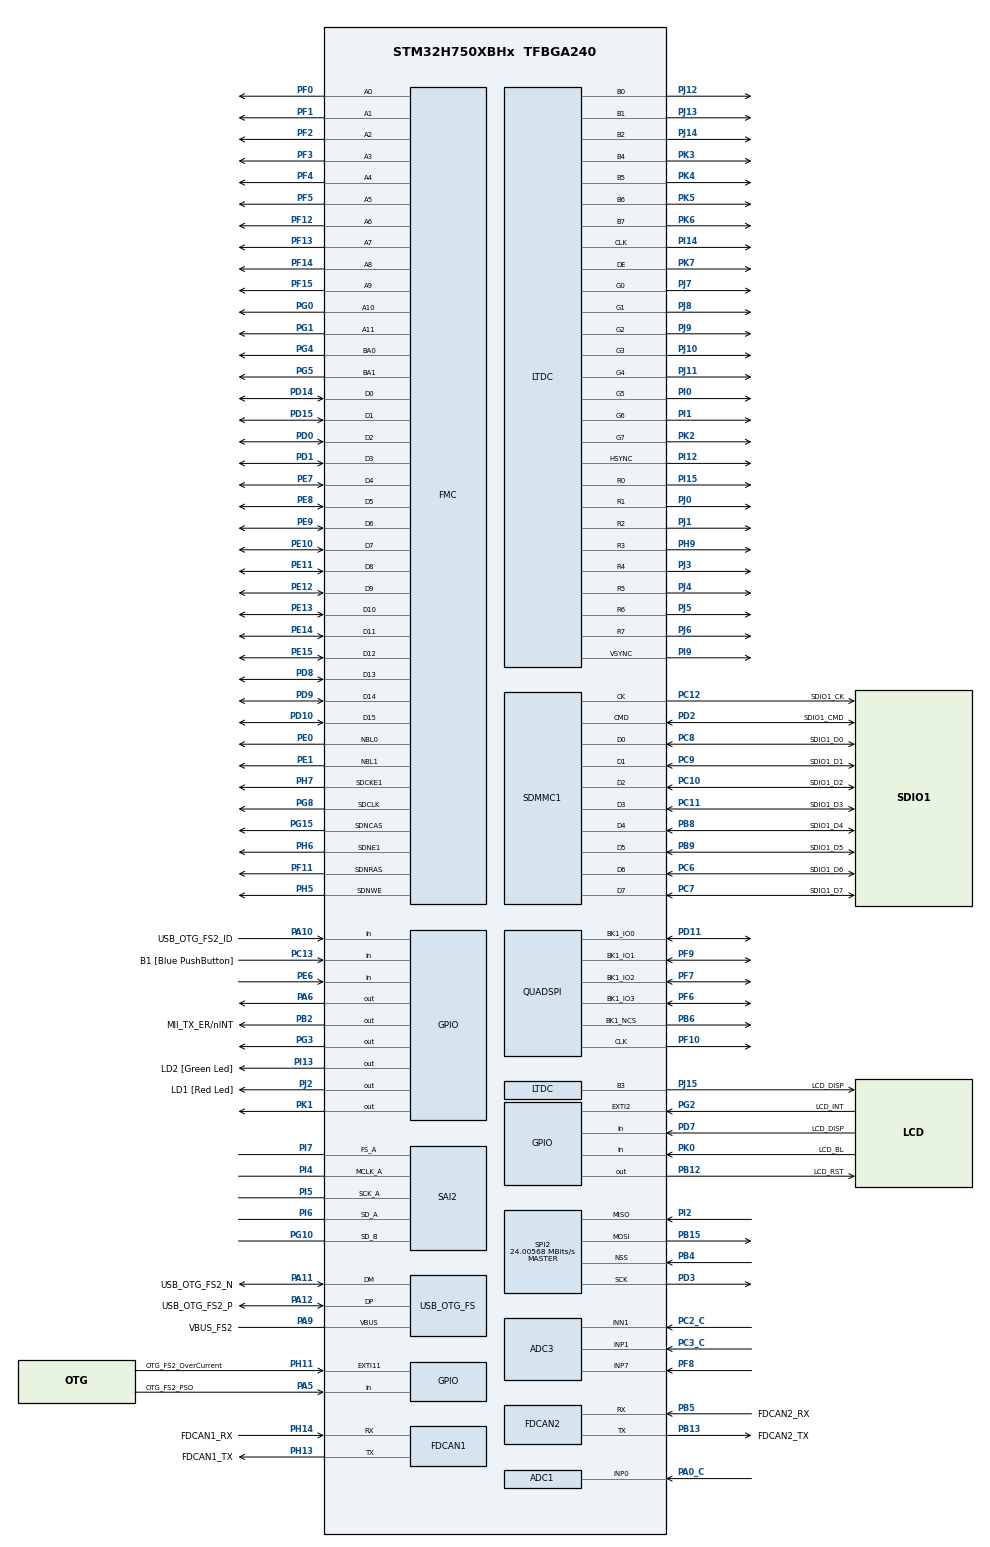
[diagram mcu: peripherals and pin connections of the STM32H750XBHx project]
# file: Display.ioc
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ADC1.Channel-0\#ChannelRegularConversion=ADC_CHANNEL_0
ADC1.NbrOfConversionFlag=1
ADC1.OffsetNumber-0\#ChannelRegularConversion=ADC_OFFSET_NONE
ADC1.Rank-0\#ChannelRegularConversion=1
ADC1.SamplingTime-0\#ChannelRegularConversion=ADC_SAMPLETIME_1CYCLE_5
ADC1.master=1
ADC2.Channel-0\#ChannelRegularConversion=ADC_CHANNEL_0
ADC2.NbrOfConversionFlag=1
ADC2.OffsetNumber-0\#ChannelRegularConversion=ADC_OFFSET_NONE
ADC2.Rank-0\#ChannelRegularConversion=1
ADC2.SamplingTime-0\#ChannelRegularConversion=ADC_SAMPLETIME_1CYCLE_5
ADC3.Channel-0\#ChannelRegularConversion=ADC_CHANNEL_7
ADC3.NbrOfConversionFlag=1
ADC3.OffsetNumber-0\#ChannelRegularConversion=ADC_OFFSET_NONE
ADC3.Rank-0\#ChannelRegularConversion=1
ADC3.SamplingTime-0\#ChannelRegularConversion=ADC_SAMPLETIME_1CYCLE_5
FDCAN1.CalculateBaudRateNominal=1000236
FDCAN1.CalculateTimeBitNominal=999
FDCAN1.CalculateTimeQuantumNominal=333.2544378698225
FDCAN2.CalculateBaudRateNominal=1000236
FDCAN2.CalculateTimeBitNominal=999
FDCAN2.CalculateTimeQuantumNominal=333.2544378698225
LTDC.ActiveH=272
LTDC.ActiveW=480
LTDC.HBP=13
LTDC.HFP=32
LTDC.HSync=41
LTDC.VSync=10
Mcu.Family=STM32H7
Mcu.Name=STM32H750XBHx
Mcu.Package=TFBGA240
NVIC.PriorityGroup=NVIC_PRIORITYGROUP_4
PA0_C.Signal=ADCx_INP0
PA1.GPIO_Label=MII_RX_CLK
PA1.Signal=ETH_RX_CLK
PA10.GPIO_Label=USB_OTG_FS2_ID
PA10.Signal=GPIO_Input
PA11.GPIO_Label=USB_OTG_FS2_N
PA11.Mode=Device_Only
PA11.Signal=USB_OTG_FS_DM
PA12.GPIO_Label=USB_OTG_FS2_P
PA12.Mode=Device_Only
PA12.Signal=USB_OTG_FS_DP
PA13\ (JTMS/SWDIO).Mode=JTAG_4_pins
PA13\ (JTMS/SWDIO).Signal=DEBUG_JTMS-SWDIO
PA14\ (JTCK/SWCLK).Mode=JTAG_4_pins
PA14\ (JTCK/SWCLK).Signal=DEBUG_JTCK-SWCLK
PA15\ (JTDI).Mode=JTAG_4_pins
PA15\ (JTDI).Signal=DEBUG_JTDI
PA1_C.Signal=ADCx_INP1
PA2.GPIO_Label=MII_MDIO
PA2.Signal=ETH_MDIO
PA5.GPIO_Label=OTG_FS2_PSO
PA5.Signal=GPIO_Input
PA6.Signal=GPIO_Output
PA7.GPIO_Label=MII_RX_DV
PA7.Signal=ETH_RX_DV
PA8.Signal=S_TIM1_CH1
PA9.GPIO_Label=VBUS_FS2
PA9.Mode=Activate_VBUS
PA9.Signal=USB_OTG_FS_VBUS
PB0.GPIO_Label=MII_RX_D2
PB0.Signal=ETH_RXD2
PB1.GPIO_Label=MII_RX_D3
PB1.Signal=ETH_RXD3
PB12.GPIO_Label=LCD_RST
PB12.Signal=GPIO_Output
PB13.GPIO_Label=FDCAN2_TX
PB13.Mode=FDCAN_Activate
PB13.Signal=FDCAN2_TX
PB15.Mode=Full_Duplex_Master
PB15.Signal=SPI2_MOSI
PB2.GPIO_Label=MII_TX_ER/nINT
PB2.Signal=GPIO_Output
PB3\ (JTDO/TRACESWO).Mode=JTAG_4_pins
PB3\ (JTDO/TRACESWO).Signal=DEBUG_JTDO-SWO
PB4\ (NJTRST).Mode=NSS_Signal_Hard_Input
PB4\ (NJTRST).Signal=SPI2_NSS
PB5.GPIO_Label=FDCAN2_RX
PB5.Mode=FDCAN_Activate
PB5.Signal=FDCAN2_RX
PB6.Mode=Single Bank 1
PB6.Signal=QUADSPI_BK1_NCS
PB8.GPIO_Label=SDIO1_D4
PB8.Mode=mmc_8_bits_Wide_bus
PB8.Signal=SDMMC1_D4
PB9.GPIO_Label=SDIO1_D5
PB9.Mode=mmc_8_bits_Wide_bus
PB9.Signal=SDMMC1_D5
PC0.Signal=ADCx_INP10
PC1.GPIO_Label=MII_MDC
PC1.Signal=ETH_MDC
PC10.GPIO_Label=SDIO1_D2
PC10.Mode=mmc_8_bits_Wide_bus
PC10.Signal=SDMMC1_D2
PC11.GPIO_Label=SDIO1_D3
PC11.Mode=mmc_8_bits_Wide_bus
PC11.Signal=SDMMC1_D3
PC12.GPIO_Label=SDIO1_CK
PC12.Mode=mmc_8_bits_Wide_bus
PC12.Signal=SDMMC1_CK
PC13.GPIO_Label=B1 [Blue PushButton]
PC13.Signal=GPIO_Input
PC14-OSC32_IN\ (OSC32_IN).GPIO_Label=OSC32_IN
PC14-OSC32_IN\ (OSC32_IN).Mode=LSE-External-Clock-Source
PC14-OSC32_IN\ (OSC32_IN).Signal=RCC_OSC32_IN
PC15-OSC32_OUT\ (OSC32_OUT).GPIO_Label=OSC32_OUT
PC15-OSC32_OUT\ (OSC32_OUT).Signal=RCC_OSC32_OUT
PC2.GPIO_Label=MII_TXD2
PC2.Signal=ETH_TXD2
PC2_C.Signal=SharedAnalog_PC2
PC3.GPIO_Label=MII_TX_CLK
PC3.Signal=ETH_TX_CLK
PC3_C.Mode=IN1-Differential
PC3_C.Signal=ADC3_INP1
PC4.GPIO_Label=MII_RXD0
PC4.Signal=ETH_RXD0
PC5.GPIO_Label=MII_RXD1
PC5.Signal=ETH_RXD1
PC6.GPIO_Label=SDIO1_D6
PC6.Mode=mmc_8_bits_Wide_bus
PC6.Signal=SDMMC1_D6
PC7.GPIO_Label=SDIO1_D7
PC7.Mode=mmc_8_bits_Wide_bus
PC7.Signal=SDMMC1_D7
PC8.GPIO_Label=SDIO1_D0
PC8.Mode=mmc_8_bits_Wide_bus
PC8.Signal=SDMMC1_D0
PC9.GPIO_Label=SDIO1_D1
PC9.Mode=mmc_8_bits_Wide_bus
PC9.Signal=SDMMC1_D1
PD0.Signal=FMC_D2_DA2
PD1.Signal=FMC_D3_DA3
PD10.Signal=FMC_D15_DA15
PD11.Mode=Single Bank 1
PD11.Signal=QUADSPI_BK1_IO0
PD14.Signal=FMC_D0_DA0
PD15.Signal=FMC_D1_DA1
PD2.GPIO_Label=SDIO1_CMD
PD2.Mode=mmc_8_bits_Wide_bus
PD2.Signal=SDMMC1_CMD
PD3.Mode=Full_Duplex_Master
PD3.Signal=SPI2_SCK
PD7.GPIO_Label=LCD_DISP
PD7.Signal=GPIO_Input
PD8.Signal=FMC_D13_DA13
PD9.Signal=FMC_D14_DA14
PE0.Signal=FMC_NBL0
PE1.Signal=FMC_NBL1
PE10.Signal=FMC_D7_DA7
PE11.Signal=FMC_D8_DA8
PE12.Signal=FMC_D9_DA9
PE13.Signal=FMC_D10_DA10
PE14.Signal=FMC_D11_DA11
PE15.Signal=FMC_D12_DA12
PE2.GPIO_Label=MII_TXD3
PE2.Signal=ETH_TXD3
PE4.Signal=SAI4_D2
PE5.Signal=SAI4_CK2
PE6.GPIO_PuPd=GPIO_PULLUP
PE6.Signal=GPIO_Input
PE7.Signal=FMC_D4_DA4
PE8.Signal=FMC_D5_DA5
PE9.Signal=FMC_D6_DA6
PF0.Signal=FMC_A0
PF1.Signal=FMC_A1
PF10.Mode=Single Bank 1
PF10.Signal=QUADSPI_CLK
PF11.Signal=FMC_SDNRAS
PF12.Signal=FMC_A6
PF13.Signal=FMC_A7
PF14.Signal=FMC_A8
PF15.Signal=FMC_A9
PF2.Signal=FMC_A2
PF3.Signal=FMC_A3
PF4.Signal=FMC_A4
PF5.Signal=FMC_A5
PF6.Mode=Single Bank 1
PF6.Signal=QUADSPI_BK1_IO3
PF7.Mode=Single Bank 1
PF7.Signal=QUADSPI_BK1_IO2
PF8.Mode=IN7-Single-Ended
PF8.Signal=ADC3_INP7
PF9.Mode=Single Bank 1
PF9.Signal=QUADSPI_BK1_IO1
PG0.Signal=FMC_A10
PG1.Signal=FMC_A11
PG10.Mode=SAI_B_SyncSlave
PG10.Signal=SAI2_SD_B
PG11.GPIO_Label=MII_TX_EN
PG11.Signal=ETH_TX_EN
PG12.GPIO_Label=MII_TXD1
PG12.Signal=ETH_TXD1
PG13.GPIO_Label=MII_TXD0
PG13.Signal=ETH_TXD0
PG15.Signal=FMC_SDNCAS
PG2.GPIO_Label=LCD_INT
PG2.Signal=GPXTI2
PG3.Signal=GPIO_Output
PG4.Signal=FMC_A14_BA0
PG5.Signal=FMC_A15_BA1
PG7.GPIO_Label=audio_Int
PG7.Signal=SAI1_MCLK_A
PG8.Signal=FMC_SDCLK
PH0-OSC_IN\ (PH0).GPIO_Label=OSC_IN
PH0-OSC_IN\ (PH0).Mode=HSE-External-Clock-Source
PH0-OSC_IN\ (PH0).Signal=RCC_OSC_IN
PH1-OSC_OUT\ (PH1).GPIO_Label=OSC_OUT
PH1-OSC_OUT\ (PH1).Signal=RCC_OSC_OUT
PH11.GPIO_Label=OTG_FS2_OverCurrent
PH11.Signal=GPXTI11
PH13.GPIO_Label=FDCAN1_TX
PH13.Mode=FDCAN_Activate
PH13.Signal=FDCAN1_TX
PH14.GPIO_Label=FDCAN1_RX
PH14.Mode=FDCAN_Activate
PH14.Signal=FDCAN1_RX
PH15.Signal=TIM8_CH3N
PH2.GPIO_Label=MII_CRS
PH2.Signal=ETH_CRS
PH3.GPIO_Label=MII_COL
PH3.Signal=ETH_COL
PH5.Signal=FMC_SDNWE
PH6.Mode=SdramChipSelect2_1
PH6.Signal=FMC_SDNE1
PH7.Mode=SdramChipSelect2_1
PH7.Signal=FMC_SDCKE1
PH9.Mode=RGB888
PH9.Signal=LTDC_R3
PI0.Mode=RGB888
PI0.Signal=LTDC_G5
PI1.Mode=RGB888
PI1.Signal=LTDC_G6
PI10.GPIO_Label=MII_RX_ER
PI10.Signal=ETH_RX_ER
PI12.Mode=RGB888
PI12.Signal=LTDC_HSYNC
PI13.GPIO_Label=LD2 [Green Led]
PI13.Signal=GPIO_Output
PI14.Mode=RGB888
PI14.Signal=LTDC_CLK
PI15.Mode=RGB888
PI15.Signal=LTDC_R0
PI2.Mode=Full_Duplex_Master
PI2.Signal=SPI2_MISO
PI4.Mode=SAI_A_MasterWithClock
PI4.Signal=SAI2_MCLK_A
PI5.Mode=SAI_A_MasterWithClock
PI5.Signal=SAI2_SCK_A
PI6.Mode=SAI_A_MasterWithClock
PI6.Signal=SAI2_SD_A
PI7.Mode=SAI_A_MasterWithClock
PI7.Signal=SAI2_FS_A
PI9.Mode=RGB888
PI9.Signal=LTDC_VSYNC
PJ0.Mode=RGB888
PJ0.Signal=LTDC_R1
PJ1.Mode=RGB888
PJ1.Signal=LTDC_R2
PJ10.Mode=RGB888
PJ10.Signal=LTDC_G3
PJ11.Mode=RGB888
PJ11.Signal=LTDC_G4
PJ12.Mode=RGB888
PJ12.Signal=LTDC_B0
PJ13.Mode=RGB888
PJ13.Signal=LTDC_B1
PJ14.Mode=RGB888
PJ14.Signal=LTDC_B2
PJ15.GPIO_Label=LCD_DISP
PJ15.Mode=RGB888
PJ15.Signal=LTDC_B3
PJ2.GPIO_Label=LD1 [Red Led]
PJ2.Signal=GPIO_Output
PJ3.Mode=RGB888
PJ3.Signal=LTDC_R4
PJ4.Mode=RGB888
PJ4.Signal=LTDC_R5
PJ5.Mode=RGB888
PJ5.Signal=LTDC_R6
PJ6.Mode=RGB888
PJ6.Signal=LTDC_R7
PJ7.Mode=RGB888
PJ7.Signal=LTDC_G0
PJ8.Mode=RGB888
PJ8.Signal=LTDC_G1
PJ9.Mode=RGB888
PJ9.Signal=LTDC_G2
PK0.GPIO_Label=LCD_BL
PK0.Signal=GPIO_Input
PK1.Signal=GPIO_Output
PK2.Mode=RGB888
PK2.Signal=LTDC_G7
PK3.Mode=RGB888
PK3.Signal=LTDC_B4
PK4.Mode=RGB888
PK4.Signal=LTDC_B5
PK5.Mode=RGB888
PK5.Signal=LTDC_B6
PK6.Mode=RGB888
PK6.Signal=LTDC_B7
PK7.Mode=RGB888
PK7.Signal=LTDC_DE
ProjectManager.HeapSize=0x200
ProjectManager.StackSize=0x400
ProjectManager.TargetToolchain=STM32CubeIDE
RCC.ADCFreq_Value=30000000
RCC.APB1Freq_Value=64000000
RCC.APB2Freq_Value=64000000
RCC.APB3Freq_Value=64000000
RCC.APB4Freq_Value=64000000
RCC.CortexFreq_Value=64000000
RCC.DIVM1=22
RCC.DIVM2=2
RCC.DIVN1=169
RCC.DIVN2=12
RCC.DIVN3=192
RCC.DIVP2=5
RCC.DIVQ1=4
RCC.HCLKFreq_Value=64000000
RCC.PLL2FRACN=0
RCC.PLL3FRACN=0
RCC.PLLFRACN=0
RCC.PWR_Regulator_Voltage_Scale=PWR_REGULATOR_VOLTAGE_SCALE2
RCC.SYSCLKFreq_VALUE=64000000
RCC.USBFreq_Value=48011363.63636364
SAI2.ErrorAudioFreq-SAI_A_MasterWithClock=-2.32 %
SAI2.Instance-SAI_A_MasterWithClock=SAI$Index_Block_A
SAI2.Instance-SAI_B_SyncSlave=SAI$Index_Block_B
SAI2.MClockEnable-SAI_A_MasterWithClock=SAI_MASTERCLOCK_ENABLE
SAI2.RealAudioFreq-SAI_A_MasterWithClock=187.544 KHz
SAI2.VirtualMode-SAI_A_MasterWithClock=VM_MASTER
SAI2.VirtualMode-SAI_B_SyncSlave=VM_SLAVE
SH.ADCx_INP0.0=ADC1_INP0,IN0-Single-Ended
SH.ADCx_INP0.1=ADC2_INP0,IN0-Single-Ended
SH.ADCx_INP1.0=ADC1_INP1
SH.ADCx_INP1.1=ADC2_INP1
SH.ADCx_INP10.0=ADC1_INP10
SH.ADCx_INP10.1=ADC3_INP10
SH.FMC_A0.0=FMC_A0,12b-sda1
SH.FMC_A1.0=FMC_A1,12b-sda1
SH.FMC_A10.0=FMC_A10,12b-sda1
SH.FMC_A11.0=FMC_A11,12b-sda1
SH.FMC_A14_BA0.0=FMC_BA0,FourSdramBanks1
SH.FMC_A15_BA1.0=FMC_BA1,FourSdramBanks1
SH.FMC_A2.0=FMC_A2,12b-sda1
SH.FMC_A3.0=FMC_A3,12b-sda1
SH.FMC_A4.0=FMC_A4,12b-sda1
SH.FMC_A5.0=FMC_A5,12b-sda1
SH.FMC_A6.0=FMC_A6,12b-sda1
SH.FMC_A7.0=FMC_A7,12b-sda1
SH.FMC_A8.0=FMC_A8,12b-sda1
SH.FMC_A9.0=FMC_A9,12b-sda1
SH.FMC_D0_DA0.0=FMC_D0,sd-16b-d1
SH.FMC_D10_DA10.0=FMC_D10,sd-16b-d1
SH.FMC_D11_DA11.0=FMC_D11,sd-16b-d1
SH.FMC_D12_DA12.0=FMC_D12,sd-16b-d1
SH.FMC_D13_DA13.0=FMC_D13,sd-16b-d1
SH.FMC_D14_DA14.0=FMC_D14,sd-16b-d1
SH.FMC_D15_DA15.0=FMC_D15,sd-16b-d1
SH.FMC_D1_DA1.0=FMC_D1,sd-16b-d1
SH.FMC_D2_DA2.0=FMC_D2,sd-16b-d1
SH.FMC_D3_DA3.0=FMC_D3,sd-16b-d1
SH.FMC_D4_DA4.0=FMC_D4,sd-16b-d1
SH.FMC_D5_DA5.0=FMC_D5,sd-16b-d1
SH.FMC_D6_DA6.0=FMC_D6,sd-16b-d1
SH.FMC_D7_DA7.0=FMC_D7,sd-16b-d1
SH.FMC_D8_DA8.0=FMC_D8,sd-16b-d1
SH.FMC_D9_DA9.0=FMC_D9,sd-16b-d1
SH.FMC_NBL0.0=FMC_NBL0,Sd2ByteEnable1
SH.FMC_NBL1.0=FMC_NBL1,Sd2ByteEnable1
SH.FMC_SDCLK.0=FMC_SDCLK,12b-sda1
SH.FMC_SDNCAS.0=FMC_SDNCAS,12b-sda1
SH.FMC_SDNRAS.0=FMC_SDNRAS,12b-sda1
SH.FMC_SDNWE.0=FMC_SDNWE,12b-sda1
SH.S_TIM1_CH1.0=TIM1_CH1
SH.SharedAnalog_PC2.0=ADC3_INP0
SH.SharedAnalog_PC2.1=ADC3_INN1,IN1-Differential
SPI2.CalculateBaudRate=24.00568 MBits/s
SPI2.Direction=SPI_DIRECTION_2LINES
SPI2.Mode=SPI_MODE_MASTER
SPI2.VirtualNSS=VM_NSSHARD
SPI2.VirtualType=VM_MASTER
USB_OTG_FS.VirtualMode=Device_Only
VP_DMA2D_VS_DMA2D.Mode=DMA2D_Activate
VP_MEMORYMAP_VS_MEMORYMAP.Mode=CurAppReg
VP_RTC_VS_RTC_Activate.Mode=RTC_Enabled
VP_TIM13_VS_ClockSourceINT.Mode=Enable_Timer
board=STM32H750B-DK

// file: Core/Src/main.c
/* USER CODE BEGIN Header */
/**
  ******************************************************************************
  * @file           : main.c
  * @brief          : Main program body
  ******************************************************************************
  * @attention
  *
  * Copyright (c) 2025 STMicroelectronics.
  * All rights reserved.
  *
  * This software is licensed under terms that can be found in the LICENSE file
  * in the root directory of this software component.
  * If no LICENSE file comes with this software, it is provided AS-IS.
  *
  ******************************************************************************
  */
/* USER CODE END Header */
#include "main.h"

/* USER CODE BEGIN Includes */
#include "stm32h750b_discovery_lcd.h"
#include "stm32_lcd.h"
/* USER CODE END Includes */

ADC_HandleTypeDef hadc1;
ADC_HandleTypeDef hadc2;
ADC_HandleTypeDef hadc3;

DMA2D_HandleTypeDef hdma2d;

FDCAN_HandleTypeDef hfdcan1;
FDCAN_HandleTypeDef hfdcan2;

LTDC_HandleTypeDef hltdc;

QSPI_HandleTypeDef hqspi;

RTC_HandleTypeDef hrtc;

SAI_HandleTypeDef hsai_BlockA2;
SAI_HandleTypeDef hsai_BlockB2;

MMC_HandleTypeDef hmmc1;

SPI_HandleTypeDef hspi2;

TIM_HandleTypeDef htim13;

PCD_HandleTypeDef hpcd_USB_OTG_FS;

SDRAM_HandleTypeDef hsdram1;

void SystemClock_Config(void);
void PeriphCommonClock_Config(void);
static void MX_GPIO_Init(void);
static void MX_ADC1_Init(void);
static void MX_ADC2_Init(void);
static void MX_ADC3_Init(void);
static void MX_FDCAN1_Init(void);
static void MX_FDCAN2_Init(void);
static void MX_FMC_Init(void);
static void MX_LTDC_Init(void);
static void MX_QUADSPI_Init(void);
static void MX_RTC_Init(void);
static void MX_SAI2_Init(void);
static void MX_SDMMC1_MMC_Init(void);
static void MX_SPI2_Init(void);
static void MX_USB_OTG_FS_PCD_Init(void);
static void MX_DMA2D_Init(void);
static void MX_TIM13_Init(void);

int main(void)
{

  /* USER CODE BEGIN 1 */
	//MPU_Config();
  /* USER CODE END 1 */

  /* MCU Configuration--------------------------------------------------------*/

  /* Reset of all peripherals, Initializes the Flash interface and the Systick. */
  HAL_Init();

  /* Configure the system clock */
  SystemClock_Config();

  /* Configure the peripherals common clocks */
  PeriphCommonClock_Config();

  /* Initialize all configured peripherals */
  MX_GPIO_Init();
  MX_ADC1_Init();
  MX_ADC2_Init();
  MX_ADC3_Init();
  MX_FDCAN1_Init();
  MX_FDCAN2_Init();
  MX_FMC_Init();
  MX_LTDC_Init();
  MX_QUADSPI_Init();
  MX_RTC_Init();
  MX_SAI2_Init();
  MX_SDMMC1_MMC_Init();
  MX_SPI2_Init();
  MX_USB_OTG_FS_PCD_Init();
  MX_DMA2D_Init();
  MX_TIM13_Init();

  /* Infinite loop */
  /* USER CODE BEGIN WHILE */

  BSP_LCD_Init(0, LCD_ORIENTATION_LANDSCAPE); // 0 = default layer
  UTIL_LCD_SetFuncDriver(&LCD_Driver);
  UTIL_LCD_SetLayer(0);
  //BSP_LCD_Clear(0, LCD_COLOR_BLUE);
  UTIL_LCD_Clear(UTIL_LCD_COLOR_BLUE);
  //BSP_LCD_DisplayStringAt(0, 0, (uint8_t *)"Hello, STM32H750B-DK!", LEFT_MODE);
  UTIL_LCD_SetFont(&Font8);
  UTIL_LCD_DisplayStringAt(10, 10, (uint8_t *)"Hello world!", LEFT_MODE);
  while (1)
  {
    /* USER CODE END WHILE */

  }
}

void SystemClock_Config(void)
{
  RCC_OscInitTypeDef RCC_OscInitStruct = {0};
  RCC_ClkInitTypeDef RCC_ClkInitStruct = {0};

  /** Supply configuration update enable
  */
  HAL_PWREx_ConfigSupply(PWR_LDO_SUPPLY);

  /** Configure the main internal regulator output voltage
  */
  __HAL_PWR_VOLTAGESCALING_CONFIG(PWR_REGULATOR_VOLTAGE_SCALE2);

  while(!__HAL_PWR_GET_FLAG(PWR_FLAG_VOSRDY)) {}

  /** Initializes the RCC Oscillators according to the specified parameters
  * in the RCC_OscInitTypeDef structure.
  */
  RCC_OscInitStruct.OscillatorType = RCC_OSCILLATORTYPE_HSI|RCC_OSCILLATORTYPE_LSI
                              |RCC_OSCILLATORTYPE_HSE;
  RCC_OscInitStruct.HSEState = RCC_HSE_BYPASS;
  RCC_OscInitStruct.HSIState = RCC_HSI_DIV1;
  RCC_OscInitStruct.HSICalibrationValue = RCC_HSICALIBRATION_DEFAULT;
  RCC_OscInitStruct.LSIState = RCC_LSI_ON;
  RCC_OscInitStruct.PLL.PLLState = RCC_PLL_ON;
  RCC_OscInitStruct.PLL.PLLSource = RCC_PLLSOURCE_HSE;
  RCC_OscInitStruct.PLL.PLLM = 22;
  RCC_OscInitStruct.PLL.PLLN = 169;
  RCC_OscInitStruct.PLL.PLLP = 2;
  RCC_OscInitStruct.PLL.PLLQ = 4;
  RCC_OscInitStruct.PLL.PLLR = 2;
  RCC_OscInitStruct.PLL.PLLRGE = RCC_PLL1VCIRANGE_0;
  RCC_OscInitStruct.PLL.PLLVCOSEL = RCC_PLL1VCOWIDE;
  RCC_OscInitStruct.PLL.PLLFRACN = 0;
  if (HAL_RCC_OscConfig(&RCC_OscInitStruct) != HAL_OK)
  {
    Error_Handler();
  }

  /** Initializes the CPU, AHB and APB buses clocks
  */
  RCC_ClkInitStruct.ClockType = RCC_CLOCKTYPE_HCLK|RCC_CLOCKTYPE_SYSCLK
                              |RCC_CLOCKTYPE_PCLK1|RCC_CLOCKTYPE_PCLK2
                              |RCC_CLOCKTYPE_D3PCLK1|RCC_CLOCKTYPE_D1PCLK1;
  RCC_ClkInitStruct.SYSCLKSource = RCC_SYSCLKSOURCE_HSI;
  RCC_ClkInitStruct.SYSCLKDivider = RCC_SYSCLK_DIV1;
  RCC_ClkInitStruct.AHBCLKDivider = RCC_HCLK_DIV1;
  RCC_ClkInitStruct.APB3CLKDivider = RCC_APB3_DIV1;
  RCC_ClkInitStruct.APB1CLKDivider = RCC_APB1_DIV1;
  RCC_ClkInitStruct.APB2CLKDivider = RCC_APB2_DIV1;
  RCC_ClkInitStruct.APB4CLKDivider = RCC_APB4_DIV1;

  if (HAL_RCC_ClockConfig(&RCC_ClkInitStruct, FLASH_LATENCY_1) != HAL_OK)
  {
    Error_Handler();
  }
}

void PeriphCommonClock_Config(void)
{
  RCC_PeriphCLKInitTypeDef PeriphClkInitStruct = {0};

  /** Initializes the peripherals clock
  */
  PeriphClkInitStruct.PeriphClockSelection = RCC_PERIPHCLK_ADC;
  PeriphClkInitStruct.PLL2.PLL2M = 2;
  PeriphClkInitStruct.PLL2.PLL2N = 12;
  PeriphClkInitStruct.PLL2.PLL2P = 5;
  PeriphClkInitStruct.PLL2.PLL2Q = 2;
  PeriphClkInitStruct.PLL2.PLL2R = 2;
  PeriphClkInitStruct.PLL2.PLL2RGE = RCC_PLL2VCIRANGE_3;
  PeriphClkInitStruct.PLL2.PLL2VCOSEL = RCC_PLL2VCOMEDIUM;
  PeriphClkInitStruct.PLL2.PLL2FRACN = 0;
  PeriphClkInitStruct.AdcClockSelection = RCC_ADCCLKSOURCE_PLL2;
  if (HAL_RCCEx_PeriphCLKConfig(&PeriphClkInitStruct) != HAL_OK)
  {
    Error_Handler();
  }
}

static void MX_ADC1_Init(void)
{

  ADC_MultiModeTypeDef multimode = {0};
  ADC_ChannelConfTypeDef sConfig = {0};

  /** Common config
  */
  hadc1.Instance = ADC1;
  hadc1.Init.ClockPrescaler = ADC_CLOCK_ASYNC_DIV1;
  hadc1.Init.Resolution = ADC_RESOLUTION_16B;
  hadc1.Init.ScanConvMode = ADC_SCAN_DISABLE;
  hadc1.Init.EOCSelection = ADC_EOC_SINGLE_CONV;
  hadc1.Init.LowPowerAutoWait = DISABLE;
  hadc1.Init.ContinuousConvMode = DISABLE;
  hadc1.Init.NbrOfConversion = 1;
  hadc1.Init.DiscontinuousConvMode = DISABLE;
  hadc1.Init.ExternalTrigConv = ADC_SOFTWARE_START;
  hadc1.Init.ExternalTrigConvEdge = ADC_EXTERNALTRIGCONVEDGE_NONE;
  hadc1.Init.ConversionDataManagement = ADC_CONVERSIONDATA_DR;
  hadc1.Init.Overrun = ADC_OVR_DATA_PRESERVED;
  hadc1.Init.LeftBitShift = ADC_LEFTBITSHIFT_NONE;
  hadc1.Init.OversamplingMode = DISABLE;
  hadc1.Init.Oversampling.Ratio = 1;
  if (HAL_ADC_Init(&hadc1) != HAL_OK)
  {
    Error_Handler();
  }

  /** Configure the ADC multi-mode
  */
  multimode.Mode = ADC_MODE_INDEPENDENT;
  if (HAL_ADCEx_MultiModeConfigChannel(&hadc1, &multimode) != HAL_OK)
  {
    Error_Handler();
  }

  /** Configure Regular Channel
  */
  sConfig.Channel = ADC_CHANNEL_0;
  sConfig.Rank = ADC_REGULAR_RANK_1;
  sConfig.SamplingTime = ADC_SAMPLETIME_1CYCLE_5;
  sConfig.SingleDiff = ADC_SINGLE_ENDED;
  sConfig.OffsetNumber = ADC_OFFSET_NONE;
  sConfig.Offset = 0;
  sConfig.OffsetSignedSaturation = DISABLE;
  if (HAL_ADC_ConfigChannel(&hadc1, &sConfig) != HAL_OK)
  {
    Error_Handler();
  }

}

static void MX_ADC2_Init(void)
{

  ADC_ChannelConfTypeDef sConfig = {0};

  /** Common config
  */
  hadc2.Instance = ADC2;
  hadc2.Init.ClockPrescaler = ADC_CLOCK_ASYNC_DIV1;
  hadc2.Init.Resolution = ADC_RESOLUTION_16B;
  hadc2.Init.ScanConvMode = ADC_SCAN_DISABLE;
  hadc2.Init.EOCSelection = ADC_EOC_SINGLE_CONV;
  hadc2.Init.LowPowerAutoWait = DISABLE;
  hadc2.Init.ContinuousConvMode = DISABLE;
  hadc2.Init.NbrOfConversion = 1;
  hadc2.Init.DiscontinuousConvMode = DISABLE;
  hadc2.Init.ExternalTrigConv = ADC_SOFTWARE_START;
  hadc2.Init.ExternalTrigConvEdge = ADC_EXTERNALTRIGCONVEDGE_NONE;
  hadc2.Init.ConversionDataManagement = ADC_CONVERSIONDATA_DR;
  hadc2.Init.Overrun = ADC_OVR_DATA_PRESERVED;
  hadc2.Init.LeftBitShift = ADC_LEFTBITSHIFT_NONE;
  hadc2.Init.OversamplingMode = DISABLE;
  hadc2.Init.Oversampling.Ratio = 1;
  if (HAL_ADC_Init(&hadc2) != HAL_OK)
  {
    Error_Handler();
  }

  /** Configure Regular Channel
  */
  sConfig.Channel = ADC_CHANNEL_0;
  sConfig.Rank = ADC_REGULAR_RANK_1;
  sConfig.SamplingTime = ADC_SAMPLETIME_1CYCLE_5;
  sConfig.SingleDiff = ADC_SINGLE_ENDED;
  sConfig.OffsetNumber = ADC_OFFSET_NONE;
  sConfig.Offset = 0;
  sConfig.OffsetSignedSaturation = DISABLE;
  if (HAL_ADC_ConfigChannel(&hadc2, &sConfig) != HAL_OK)
  {
    Error_Handler();
  }

}

static void MX_ADC3_Init(void)
{

  ADC_ChannelConfTypeDef sConfig = {0};

  /** Common config
  */
  hadc3.Instance = ADC3;
  hadc3.Init.ClockPrescaler = ADC_CLOCK_ASYNC_DIV1;
  hadc3.Init.Resolution = ADC_RESOLUTION_16B;
  hadc3.Init.ScanConvMode = ADC_SCAN_DISABLE;
  hadc3.Init.EOCSelection = ADC_EOC_SINGLE_CONV;
  hadc3.Init.LowPowerAutoWait = DISABLE;
  hadc3.Init.ContinuousConvMode = DISABLE;
  hadc3.Init.NbrOfConversion = 1;
  hadc3.Init.DiscontinuousConvMode = DISABLE;
  hadc3.Init.ExternalTrigConv = ADC_SOFTWARE_START;
  hadc3.Init.ExternalTrigConvEdge = ADC_EXTERNALTRIGCONVEDGE_NONE;
  hadc3.Init.ConversionDataManagement = ADC_CONVERSIONDATA_DR;
  hadc3.Init.Overrun = ADC_OVR_DATA_PRESERVED;
  hadc3.Init.LeftBitShift = ADC_LEFTBITSHIFT_NONE;
  hadc3.Init.OversamplingMode = DISABLE;
  hadc3.Init.Oversampling.Ratio = 1;
  if (HAL_ADC_Init(&hadc3) != HAL_OK)
  {
    Error_Handler();
  }

  /** Configure Regular Channel
  */
  sConfig.Channel = ADC_CHANNEL_7;
  sConfig.Rank = ADC_REGULAR_RANK_1;
  sConfig.SamplingTime = ADC_SAMPLETIME_1CYCLE_5;
  sConfig.SingleDiff = ADC_SINGLE_ENDED;
  sConfig.OffsetNumber = ADC_OFFSET_NONE;
  sConfig.Offset = 0;
  sConfig.OffsetSignedSaturation = DISABLE;
  if (HAL_ADC_ConfigChannel(&hadc3, &sConfig) != HAL_OK)
  {
    Error_Handler();
  }

}

static void MX_DMA2D_Init(void)
{

  hdma2d.Instance = DMA2D;
  hdma2d.Init.Mode = DMA2D_M2M;
  hdma2d.Init.ColorMode = DMA2D_OUTPUT_ARGB8888;
  hdma2d.Init.OutputOffset = 0;
  hdma2d.LayerCfg[1].InputOffset = 0;
  hdma2d.LayerCfg[1].InputColorMode = DMA2D_INPUT_ARGB8888;
  hdma2d.LayerCfg[1].AlphaMode = DMA2D_NO_MODIF_ALPHA;
  hdma2d.LayerCfg[1].InputAlpha = 0;
  hdma2d.LayerCfg[1].AlphaInverted = DMA2D_REGULAR_ALPHA;
  hdma2d.LayerCfg[1].RedBlueSwap = DMA2D_RB_REGULAR;
  hdma2d.LayerCfg[1].ChromaSubSampling = DMA2D_NO_CSS;
  if (HAL_DMA2D_Init(&hdma2d) != HAL_OK)
  {
    Error_Handler();
  }
  if (HAL_DMA2D_ConfigLayer(&hdma2d, 1) != HAL_OK)
  {
    Error_Handler();
  }

}

static void MX_FDCAN1_Init(void)
{

  hfdcan1.Instance = FDCAN1;
  hfdcan1.Init.FrameFormat = FDCAN_FRAME_CLASSIC;
  hfdcan1.Init.Mode = FDCAN_MODE_NORMAL;
  hfdcan1.Init.AutoRetransmission = DISABLE;
  hfdcan1.Init.TransmitPause = DISABLE;
  hfdcan1.Init.ProtocolException = DISABLE;
  hfdcan1.Init.NominalPrescaler = 16;
  hfdcan1.Init.NominalSyncJumpWidth = 1;
  hfdcan1.Init.NominalTimeSeg1 = 1;
  hfdcan1.Init.NominalTimeSeg2 = 1;
  hfdcan1.Init.DataPrescaler = 1;
  hfdcan1.Init.DataSyncJumpWidth = 1;
  hfdcan1.Init.DataTimeSeg1 = 1;
  hfdcan1.Init.DataTimeSeg2 = 1;
  hfdcan1.Init.MessageRAMOffset = 0;
  hfdcan1.Init.StdFiltersNbr = 0;
  hfdcan1.Init.ExtFiltersNbr = 0;
  hfdcan1.Init.RxFifo0ElmtsNbr = 0;
  hfdcan1.Init.RxFifo0ElmtSize = FDCAN_DATA_BYTES_8;
  hfdcan1.Init.RxFifo1ElmtsNbr = 0;
  hfdcan1.Init.RxFifo1ElmtSize = FDCAN_DATA_BYTES_8;
  hfdcan1.Init.RxBuffersNbr = 0;
  hfdcan1.Init.RxBufferSize = FDCAN_DATA_BYTES_8;
  hfdcan1.Init.TxEventsNbr = 0;
  hfdcan1.Init.TxBuffersNbr = 0;
  hfdcan1.Init.TxFifoQueueElmtsNbr = 0;
  hfdcan1.Init.TxFifoQueueMode = FDCAN_TX_FIFO_OPERATION;
  hfdcan1.Init.TxElmtSize = FDCAN_DATA_BYTES_8;
  if (HAL_FDCAN_Init(&hfdcan1) != HAL_OK)
  {
    Error_Handler();
  }

}

static void MX_FDCAN2_Init(void)
{

  hfdcan2.Instance = FDCAN2;
  hfdcan2.Init.FrameFormat = FDCAN_FRAME_CLASSIC;
  hfdcan2.Init.Mode = FDCAN_MODE_NORMAL;
  hfdcan2.Init.AutoRetransmission = DISABLE;
  hfdcan2.Init.TransmitPause = DISABLE;
  hfdcan2.Init.ProtocolException = DISABLE;
  hfdcan2.Init.NominalPrescaler = 16;
  hfdcan2.Init.NominalSyncJumpWidth = 1;
  hfdcan2.Init.NominalTimeSeg1 = 1;
  hfdcan2.Init.NominalTimeSeg2 = 1;
  hfdcan2.Init.DataPrescaler = 1;
  hfdcan2.Init.DataSyncJumpWidth = 1;
  hfdcan2.Init.DataTimeSeg1 = 1;
  hfdcan2.Init.DataTimeSeg2 = 1;
  hfdcan2.Init.MessageRAMOffset = 0;
  hfdcan2.Init.StdFiltersNbr = 0;
  hfdcan2.Init.ExtFiltersNbr = 0;
  hfdcan2.Init.RxFifo0ElmtsNbr = 0;
  hfdcan2.Init.RxFifo0ElmtSize = FDCAN_DATA_BYTES_8;
  hfdcan2.Init.RxFifo1ElmtsNbr = 0;
  hfdcan2.Init.RxFifo1ElmtSize = FDCAN_DATA_BYTES_8;
  hfdcan2.Init.RxBuffersNbr = 0;
  hfdcan2.Init.RxBufferSize = FDCAN_DATA_BYTES_8;
  hfdcan2.Init.TxEventsNbr = 0;
  hfdcan2.Init.TxBuffersNbr = 0;
  hfdcan2.Init.TxFifoQueueElmtsNbr = 0;
  hfdcan2.Init.TxFifoQueueMode = FDCAN_TX_FIFO_OPERATION;
  hfdcan2.Init.TxElmtSize = FDCAN_DATA_BYTES_8;
  if (HAL_FDCAN_Init(&hfdcan2) != HAL_OK)
  {
    Error_Handler();
  }

}

static void MX_LTDC_Init(void)
{

  /* USER CODE BEGIN LTDC_Init 0 */
//
  /* USER CODE END LTDC_Init 0 */

  LTDC_LayerCfgTypeDef pLayerCfg = {0};
  LTDC_LayerCfgTypeDef pLayerCfg1 = {0};

  /* USER CODE BEGIN LTDC_Init 1 */
//
  /* USER CODE END LTDC_Init 1 */
  hltdc.Instance = LTDC;
  hltdc.Init.HSPolarity = LTDC_HSPOLARITY_AL;
  hltdc.Init.VSPolarity = LTDC_VSPOLARITY_AL;
  hltdc.Init.DEPolarity = LTDC_DEPOLARITY_AL;
  hltdc.Init.PCPolarity = LTDC_PCPOLARITY_IPC;
  hltdc.Init.HorizontalSync = 40;
  hltdc.Init.VerticalSync = 9;
  hltdc.Init.AccumulatedHBP = 53;
  hltdc.Init.AccumulatedVBP = 11;
  hltdc.Init.AccumulatedActiveW = 533;
  hltdc.Init.AccumulatedActiveH = 283;
  hltdc.Init.TotalWidth = 565;
  hltdc.Init.TotalHeigh = 285;
  hltdc.Init.Backcolor.Blue = 0;
  hltdc.Init.Backcolor.Green = 0;
  hltdc.Init.Backcolor.Red = 0;
  if (HAL_LTDC_Init(&hltdc) != HAL_OK)
  {
    Error_Handler();
  }
  pLayerCfg.WindowX0 = 0;
  pLayerCfg.WindowX1 = 0;
  pLayerCfg.WindowY0 = 0;
  pLayerCfg.WindowY1 = 0;
  pLayerCfg.PixelFormat = LTDC_PIXEL_FORMAT_ARGB8888;
  pLayerCfg.Alpha = 0;
  pLayerCfg.Alpha0 = 0;
  pLayerCfg.BlendingFactor1 = LTDC_BLENDING_FACTOR1_CA;
  pLayerCfg.BlendingFactor2 = LTDC_BLENDING_FACTOR2_CA;
  pLayerCfg.FBStartAdress = 0;
  pLayerCfg.ImageWidth = 0;
  pLayerCfg.ImageHeight = 0;
  pLayerCfg.Backcolor.Blue = 0;
  pLayerCfg.Backcolor.Green = 0;
  pLayerCfg.Backcolor.Red = 0;
  if (HAL_LTDC_ConfigLayer(&hltdc, &pLayerCfg, 0) != HAL_OK)
  {
    Error_Handler();
  }
  pLayerCfg1.WindowX0 = 0;
  pLayerCfg1.WindowX1 = 0;
  pLayerCfg1.WindowY0 = 0;
  pLayerCfg1.WindowY1 = 0;
  pLayerCfg1.PixelFormat = LTDC_PIXEL_FORMAT_ARGB8888;
  pLayerCfg1.Alpha = 0;
  pLayerCfg1.Alpha0 = 0;
  pLayerCfg1.BlendingFactor1 = LTDC_BLENDING_FACTOR1_CA;
  pLayerCfg1.BlendingFactor2 = LTDC_BLENDING_FACTOR2_CA;
  pLayerCfg1.FBStartAdress = 0;
  pLayerCfg1.ImageWidth = 0;
  pLayerCfg1.ImageHeight = 0;
  pLayerCfg1.Backcolor.Blue = 0;
  pLayerCfg1.Backcolor.Green = 0;
  pLayerCfg1.Backcolor.Red = 0;
  if (HAL_LTDC_ConfigLayer(&hltdc, &pLayerCfg1, 1) != HAL_OK)
  {
    Error_Handler();
  }
  /* USER CODE BEGIN LTDC_Init 2 */
//
  /* USER CODE END LTDC_Init 2 */

}

static void MX_QUADSPI_Init(void)
{

  /* QUADSPI parameter configuration*/
  hqspi.Instance = QUADSPI;
  hqspi.Init.ClockPrescaler = 255;
  hqspi.Init.FifoThreshold = 1;
  hqspi.Init.SampleShifting = QSPI_SAMPLE_SHIFTING_NONE;
  hqspi.Init.FlashSize = 1;
  hqspi.Init.ChipSelectHighTime = QSPI_CS_HIGH_TIME_1_CYCLE;
  hqspi.Init.ClockMode = QSPI_CLOCK_MODE_0;
  hqspi.Init.FlashID = QSPI_FLASH_ID_1;
  hqspi.Init.DualFlash = QSPI_DUALFLASH_DISABLE;
  if (HAL_QSPI_Init(&hqspi) != HAL_OK)
  {
    Error_Handler();
  }

}

static void MX_RTC_Init(void)
{

  /** Initialize RTC Only
  */
  hrtc.Instance = RTC;
  hrtc.Init.HourFormat = RTC_HOURFORMAT_24;
  hrtc.Init.AsynchPrediv = 127;
  hrtc.Init.SynchPrediv = 255;
  hrtc.Init.OutPut = RTC_OUTPUT_DISABLE;
  hrtc.Init.OutPutPolarity = RTC_OUTPUT_POLARITY_HIGH;
  hrtc.Init.OutPutType = RTC_OUTPUT_TYPE_OPENDRAIN;
  hrtc.Init.OutPutRemap = RTC_OUTPUT_REMAP_NONE;
  if (HAL_RTC_Init(&hrtc) != HAL_OK)
  {
    Error_Handler();
  }

}

static void MX_SAI2_Init(void)
{

  hsai_BlockA2.Instance = SAI2_Block_A;
  hsai_BlockA2.Init.Protocol = SAI_FREE_PROTOCOL;
  hsai_BlockA2.Init.AudioMode = SAI_MODEMASTER_TX;
  hsai_BlockA2.Init.DataSize = SAI_DATASIZE_8;
  hsai_BlockA2.Init.FirstBit = SAI_FIRSTBIT_MSB;
  hsai_BlockA2.Init.ClockStrobing = SAI_CLOCKSTROBING_FALLINGEDGE;
  hsai_BlockA2.Init.Synchro = SAI_ASYNCHRONOUS;
  hsai_BlockA2.Init.OutputDrive = SAI_OUTPUTDRIVE_DISABLE;
  hsai_BlockA2.Init.NoDivider = SAI_MCK_OVERSAMPLING_DISABLE;
  hsai_BlockA2.Init.MckOverSampling = SAI_MCK_OVERSAMPLING_DISABLE;
  hsai_BlockA2.Init.FIFOThreshold = SAI_FIFOTHRESHOLD_EMPTY;
  hsai_BlockA2.Init.AudioFrequency = SAI_AUDIO_FREQUENCY_192K;
  hsai_BlockA2.Init.SynchroExt = SAI_SYNCEXT_DISABLE;
  hsai_BlockA2.Init.MonoStereoMode = SAI_STEREOMODE;
  hsai_BlockA2.Init.CompandingMode = SAI_NOCOMPANDING;
  hsai_BlockA2.Init.TriState = SAI_OUTPUT_NOTRELEASED;
  hsai_BlockA2.Init.PdmInit.Activation = DISABLE;
  hsai_BlockA2.Init.PdmInit.MicPairsNbr = 1;
  hsai_BlockA2.Init.PdmInit.ClockEnable = SAI_PDM_CLOCK1_ENABLE;
  hsai_BlockA2.FrameInit.FrameLength = 8;
  hsai_BlockA2.FrameInit.ActiveFrameLength = 1;
  hsai_BlockA2.FrameInit.FSDefinition = SAI_FS_STARTFRAME;
  hsai_BlockA2.FrameInit.FSPolarity = SAI_FS_ACTIVE_LOW;
  hsai_BlockA2.FrameInit.FSOffset = SAI_FS_FIRSTBIT;
  hsai_BlockA2.SlotInit.FirstBitOffset = 0;
  hsai_BlockA2.SlotInit.SlotSize = SAI_SLOTSIZE_DATASIZE;
  hsai_BlockA2.SlotInit.SlotNumber = 1;
  hsai_BlockA2.SlotInit.SlotActive = 0x00000000;
  if (HAL_SAI_Init(&hsai_BlockA2) != HAL_OK)
  {
    Error_Handler();
  }
  hsai_BlockB2.Instance = SAI2_Block_B;
  hsai_BlockB2.Init.Protocol = SAI_FREE_PROTOCOL;
  hsai_BlockB2.Init.AudioMode = SAI_MODESLAVE_RX;
  hsai_BlockB2.Init.DataSize = SAI_DATASIZE_8;
  hsai_BlockB2.Init.FirstBit = SAI_FIRSTBIT_MSB;
  hsai_BlockB2.Init.ClockStrobing = SAI_CLOCKSTROBING_FALLINGEDGE;
  hsai_BlockB2.Init.Synchro = SAI_SYNCHRONOUS;
  hsai_BlockB2.Init.OutputDrive = SAI_OUTPUTDRIVE_DISABLE;
  hsai_BlockB2.Init.MckOverSampling = SAI_MCK_OVERSAMPLING_DISABLE;
  hsai_BlockB2.Init.FIFOThreshold = SAI_FIFOTHRESHOLD_EMPTY;
  hsai_BlockB2.Init.SynchroExt = SAI_SYNCEXT_DISABLE;
  hsai_BlockB2.Init.MonoStereoMode = SAI_STEREOMODE;
  hsai_BlockB2.Init.CompandingMode = SAI_NOCOMPANDING;
  hsai_BlockB2.Init.TriState = SAI_OUTPUT_NOTRELEASED;
  hsai_BlockB2.Init.PdmInit.Activation = DISABLE;
  hsai_BlockB2.Init.PdmInit.MicPairsNbr = 1;
  hsai_BlockB2.Init.PdmInit.ClockEnable = SAI_PDM_CLOCK1_ENABLE;
  hsai_BlockB2.FrameInit.FrameLength = 8;
  hsai_BlockB2.FrameInit.ActiveFrameLength = 1;
  hsai_BlockB2.FrameInit.FSDefinition = SAI_FS_STARTFRAME;
  hsai_BlockB2.FrameInit.FSPolarity = SAI_FS_ACTIVE_LOW;
  hsai_BlockB2.FrameInit.FSOffset = SAI_FS_FIRSTBIT;
  hsai_BlockB2.SlotInit.FirstBitOffset = 0;
  hsai_BlockB2.SlotInit.SlotSize = SAI_SLOTSIZE_DATASIZE;
  hsai_BlockB2.SlotInit.SlotNumber = 1;
  hsai_BlockB2.SlotInit.SlotActive = 0x00000000;
  if (HAL_SAI_Init(&hsai_BlockB2) != HAL_OK)
  {
    Error_Handler();
  }

}

static void MX_SDMMC1_MMC_Init(void)
{

  hmmc1.Instance = SDMMC1;
  hmmc1.Init.ClockEdge = SDMMC_CLOCK_EDGE_RISING;
  hmmc1.Init.ClockPowerSave = SDMMC_CLOCK_POWER_SAVE_DISABLE;
  hmmc1.Init.BusWide = SDMMC_BUS_WIDE_8B;
  hmmc1.Init.HardwareFlowControl = SDMMC_HARDWARE_FLOW_CONTROL_DISABLE;
  hmmc1.Init.ClockDiv = 0;
  if (HAL_MMC_Init(&hmmc1) != HAL_OK)
  {
    Error_Handler();
  }

}

static void MX_SPI2_Init(void)
{

  /* SPI2 parameter configuration*/
  hspi2.Instance = SPI2;
  hspi2.Init.Mode = SPI_MODE_MASTER;
  hspi2.Init.Direction = SPI_DIRECTION_2LINES;
  hspi2.Init.DataSize = SPI_DATASIZE_4BIT;
  hspi2.Init.CLKPolarity = SPI_POLARITY_LOW;
  hspi2.Init.CLKPhase = SPI_PHASE_1EDGE;
  hspi2.Init.NSS = SPI_NSS_HARD_INPUT;
  hspi2.Init.BaudRatePrescaler = SPI_BAUDRATEPRESCALER_2;
  hspi2.Init.FirstBit = SPI_FIRSTBIT_MSB;
  hspi2.Init.TIMode = SPI_TIMODE_DISABLE;
  hspi2.Init.CRCCalculation = SPI_CRCCALCULATION_DISABLE;
  hspi2.Init.CRCPolynomial = 0x0;
  hspi2.Init.NSSPMode = SPI_NSS_PULSE_ENABLE;
  hspi2.Init.NSSPolarity = SPI_NSS_POLARITY_LOW;
  hspi2.Init.FifoThreshold = SPI_FIFO_THRESHOLD_01DATA;
  hspi2.Init.TxCRCInitializationPattern = SPI_CRC_INITIALIZATION_ALL_ZERO_PATTERN;
  hspi2.Init.RxCRCInitializationPattern = SPI_CRC_INITIALIZATION_ALL_ZERO_PATTERN;
  hspi2.Init.MasterSSIdleness = SPI_MASTER_SS_IDLENESS_00CYCLE;
  hspi2.Init.MasterInterDataIdleness = SPI_MASTER_INTERDATA_IDLENESS_00CYCLE;
  hspi2.Init.MasterReceiverAutoSusp = SPI_MASTER_RX_AUTOSUSP_DISABLE;
  hspi2.Init.MasterKeepIOState = SPI_MASTER_KEEP_IO_STATE_DISABLE;
  hspi2.Init.IOSwap = SPI_IO_SWAP_DISABLE;
  if (HAL_SPI_Init(&hspi2) != HAL_OK)
  {
    Error_Handler();
  }

}

static void MX_TIM13_Init(void)
{

  htim13.Instance = TIM13;
  htim13.Init.Prescaler = 0;
  htim13.Init.CounterMode = TIM_COUNTERMODE_UP;
  htim13.Init.Period = 65535;
  htim13.Init.ClockDivision = TIM_CLOCKDIVISION_DIV1;
  htim13.Init.AutoReloadPreload = TIM_AUTORELOAD_PRELOAD_DISABLE;
  if (HAL_TIM_Base_Init(&htim13) != HAL_OK)
  {
    Error_Handler();
  }

}

static void MX_USB_OTG_FS_PCD_Init(void)
{

  hpcd_USB_OTG_FS.Instance = USB_OTG_FS;
  hpcd_USB_OTG_FS.Init.dev_endpoints = 9;
  hpcd_USB_OTG_FS.Init.speed = PCD_SPEED_FULL;
  hpcd_USB_OTG_FS.Init.dma_enable = DISABLE;
  hpcd_USB_OTG_FS.Init.phy_itface = PCD_PHY_EMBEDDED;
  hpcd_USB_OTG_FS.Init.Sof_enable = DISABLE;
  hpcd_USB_OTG_FS.Init.low_power_enable = DISABLE;
  hpcd_USB_OTG_FS.Init.lpm_enable = DISABLE;
  hpcd_USB_OTG_FS.Init.battery_charging_enable = ENABLE;
  hpcd_USB_OTG_FS.Init.vbus_sensing_enable = ENABLE;
  hpcd_USB_OTG_FS.Init.use_dedicated_ep1 = DISABLE;
  if (HAL_PCD_Init(&hpcd_USB_OTG_FS) != HAL_OK)
  {
    Error_Handler();
  }

}

/* FMC initialization function */
static void MX_FMC_Init(void)
{

  FMC_SDRAM_TimingTypeDef SdramTiming = {0};

  /** Perform the SDRAM1 memory initialization sequence
  */
  hsdram1.Instance = FMC_SDRAM_DEVICE;
  /* hsdram1.Init */
  hsdram1.Init.SDBank = FMC_SDRAM_BANK2;
  hsdram1.Init.ColumnBitsNumber = FMC_SDRAM_COLUMN_BITS_NUM_8;
  hsdram1.Init.RowBitsNumber = FMC_SDRAM_ROW_BITS_NUM_12;
  hsdram1.Init.MemoryDataWidth = FMC_SDRAM_MEM_BUS_WIDTH_16;
  hsdram1.Init.InternalBankNumber = FMC_SDRAM_INTERN_BANKS_NUM_4;
  hsdram1.Init.CASLatency = FMC_SDRAM_CAS_LATENCY_1;
  hsdram1.Init.WriteProtection = FMC_SDRAM_WRITE_PROTECTION_DISABLE;
  hsdram1.Init.SDClockPeriod = FMC_SDRAM_CLOCK_DISABLE;
  hsdram1.Init.ReadBurst = FMC_SDRAM_RBURST_DISABLE;
  hsdram1.Init.ReadPipeDelay = FMC_SDRAM_RPIPE_DELAY_0;
  /* SdramTiming */
  SdramTiming.LoadToActiveDelay = 16;
  SdramTiming.ExitSelfRefreshDelay = 16;
  SdramTiming.SelfRefreshTime = 16;
  SdramTiming.RowCycleDelay = 16;
  SdramTiming.WriteRecoveryTime = 16;
  SdramTiming.RPDelay = 16;
  SdramTiming.RCDDelay = 16;

  if (HAL_SDRAM_Init(&hsdram1, &SdramTiming) != HAL_OK)
  {
    Error_Handler( );
  }

}

static void MX_GPIO_Init(void)
{
  GPIO_InitTypeDef GPIO_InitStruct = {0};

  /* GPIO Ports Clock Enable */
  __HAL_RCC_GPIOI_CLK_ENABLE();
  __HAL_RCC_GPIOB_CLK_ENABLE();
  __HAL_RCC_GPIOK_CLK_ENABLE();
  __HAL_RCC_GPIOG_CLK_ENABLE();
  __HAL_RCC_GPIOC_CLK_ENABLE();
  __HAL_RCC_GPIOA_CLK_ENABLE();
  __HAL_RCC_GPIOE_CLK_ENABLE();
  __HAL_RCC_GPIOJ_CLK_ENABLE();
  __HAL_RCC_GPIOD_CLK_ENABLE();
  __HAL_RCC_GPIOH_CLK_ENABLE();
  __HAL_RCC_GPIOF_CLK_ENABLE();

  /*Configure GPIO pin Output Level */
  HAL_GPIO_WritePin(LD2_GPIO_Port, LD2_Pin, GPIO_PIN_RESET);

  /*Configure GPIO pin Output Level */
  HAL_GPIO_WritePin(GPIOG, GPIO_PIN_3, GPIO_PIN_RESET);

  /*Configure GPIO pin Output Level */
  HAL_GPIO_WritePin(GPIOK, GPIO_PIN_1, GPIO_PIN_RESET);

  /*Configure GPIO pin Output Level */
  HAL_GPIO_WritePin(GPIOA, GPIO_PIN_6, GPIO_PIN_RESET);

  /*Configure GPIO pin Output Level */
  HAL_GPIO_WritePin(GPIOB, MII_TX_ER_nINT_Pin|LCD_RST_Pin, GPIO_PIN_RESET);

  /*Configure GPIO pin Output Level */
  HAL_GPIO_WritePin(LD1_GPIO_Port, LD1_Pin, GPIO_PIN_RESET);

  /*Configure GPIO pins : MII_TX_EN_Pin MII_TXD1_Pin MII_TXD0_Pin */
  GPIO_InitStruct.Pin = MII_TX_EN_Pin|MII_TXD1_Pin|MII_TXD0_Pin;
  GPIO_InitStruct.Mode = GPIO_MODE_AF_PP;
  GPIO_InitStruct.Pull = GPIO_NOPULL;
  GPIO_InitStruct.Speed = GPIO_SPEED_FREQ_LOW;
  GPIO_InitStruct.Alternate = GPIO_AF11_ETH;
  HAL_GPIO_Init(GPIOG, &GPIO_InitStruct);

  /*Configure GPIO pin : PH15 */
  GPIO_InitStruct.Pin = GPIO_PIN_15;
  GPIO_InitStruct.Mode = GPIO_MODE_AF_PP;
  GPIO_InitStruct.Pull = GPIO_NOPULL;
  GPIO_InitStruct.Speed = GPIO_SPEED_FREQ_LOW;
  GPIO_InitStruct.Alternate = GPIO_AF3_TIM8;
  HAL_GPIO_Init(GPIOH, &GPIO_InitStruct);

  /*Configure GPIO pin : MII_TXD3_Pin */
  GPIO_InitStruct.Pin = MII_TXD3_Pin;
  GPIO_InitStruct.Mode = GPIO_MODE_AF_PP;
  GPIO_InitStruct.Pull = GPIO_NOPULL;
  GPIO_InitStruct.Speed = GPIO_SPEED_FREQ_LOW;
  GPIO_InitStruct.Alternate = GPIO_AF11_ETH;
  HAL_GPIO_Init(MII_TXD3_GPIO_Port, &GPIO_InitStruct);

  /*Configure GPIO pin : LCD_DISPD7_Pin */
  GPIO_InitStruct.Pin = LCD_DISPD7_Pin;
  GPIO_InitStruct.Mode = GPIO_MODE_INPUT;
  GPIO_InitStruct.Pull = GPIO_NOPULL;
  HAL_GPIO_Init(LCD_DISPD7_GPIO_Port, &GPIO_InitStruct);

  /*Configure GPIO pins : PE5 PE4 */
  GPIO_InitStruct.Pin = GPIO_PIN_5|GPIO_PIN_4;
  GPIO_InitStruct.Mode = GPIO_MODE_AF_PP;
  GPIO_InitStruct.Pull = GPIO_NOPULL;
  GPIO_InitStruct.Speed = GPIO_SPEED_FREQ_LOW;
  GPIO_InitStruct.Alternate = GPIO_AF10_SAI4;
  HAL_GPIO_Init(GPIOE, &GPIO_InitStruct);

  /*Configure GPIO pins : USB_OTG_FS2_ID_Pin OTG_FS2_PSO_Pin */
  GPIO_InitStruct.Pin = USB_OTG_FS2_ID_Pin|OTG_FS2_PSO_Pin;
  GPIO_InitStruct.Mode = GPIO_MODE_INPUT;
  GPIO_InitStruct.Pull = GPIO_NOPULL;
  HAL_GPIO_Init(GPIOA, &GPIO_InitStruct);

  /*Configure GPIO pin : B1_Pin */
  GPIO_InitStruct.Pin = B1_Pin;
  GPIO_InitStruct.Mode = GPIO_MODE_INPUT;
  GPIO_InitStruct.Pull = GPIO_NOPULL;
  HAL_GPIO_Init(B1_GPIO_Port, &GPIO_InitStruct);

  /*Configure GPIO pin : PE6 */
  GPIO_InitStruct.Pin = GPIO_PIN_6;
  GPIO_InitStruct.Mode = GPIO_MODE_INPUT;
  GPIO_InitStruct.Pull = GPIO_PULLUP;
  HAL_GPIO_Init(GPIOE, &GPIO_InitStruct);

  /*Configure GPIO pin : PA8 */
  GPIO_InitStruct.Pin = GPIO_PIN_8;
  GPIO_InitStruct.Mode = GPIO_MODE_AF_PP;
  GPIO_InitStruct.Pull = GPIO_NOPULL;
  GPIO_InitStruct.Speed = GPIO_SPEED_FREQ_LOW;
  GPIO_InitStruct.Alternate = GPIO_AF1_TIM1;
  HAL_GPIO_Init(GPIOA, &GPIO_InitStruct);

  /*Configure GPIO pin : MII_RX_ER_Pin */
  GPIO_InitStruct.Pin = MII_RX_ER_Pin;
  GPIO_InitStruct.Mode = GPIO_MODE_AF_PP;
  GPIO_InitStruct.Pull = GPIO_NOPULL;
  GPIO_InitStruct.Speed = GPIO_SPEED_FREQ_LOW;
  GPIO_InitStruct.Alternate = GPIO_AF11_ETH;
  HAL_GPIO_Init(MII_RX_ER_GPIO_Port, &GPIO_InitStruct);

  /*Configure GPIO pin : audio_Int_Pin */
  GPIO_InitStruct.Pin = audio_Int_Pin;
  GPIO_InitStruct.Mode = GPIO_MODE_AF_PP;
  GPIO_InitStruct.Pull = GPIO_NOPULL;
  GPIO_InitStruct.Speed = GPIO_SPEED_FREQ_LOW;
  GPIO_InitStruct.Alternate = GPIO_AF6_SAI1;
  HAL_GPIO_Init(audio_Int_GPIO_Port, &GPIO_InitStruct);

  /*Configure GPIO pin : LD2_Pin */
  GPIO_InitStruct.Pin = LD2_Pin;
  GPIO_InitStruct.Mode = GPIO_MODE_OUTPUT_PP;
  GPIO_InitStruct.Pull = GPIO_NOPULL;
  GPIO_InitStruct.Speed = GPIO_SPEED_FREQ_LOW;
  HAL_GPIO_Init(LD2_GPIO_Port, &GPIO_InitStruct);

  /*Configure GPIO pin : PG3 */
  GPIO_InitStruct.Pin = GPIO_PIN_3;
  GPIO_InitStruct.Mode = GPIO_MODE_OUTPUT_PP;
  GPIO_InitStruct.Pull = GPIO_NOPULL;
  GPIO_InitStruct.Speed = GPIO_SPEED_FREQ_LOW;
  HAL_GPIO_Init(GPIOG, &GPIO_InitStruct);

  /*Configure GPIO pin : LCD_INT_Pin */
  GPIO_InitStruct.Pin = LCD_INT_Pin;
  GPIO_InitStruct.Mode = GPIO_MODE_IT_RISING;
  GPIO_InitStruct.Pull = GPIO_NOPULL;
  HAL_GPIO_Init(LCD_INT_GPIO_Port, &GPIO_InitStruct);

  /*Configure GPIO pin : LCD_BL_Pin */
  GPIO_InitStruct.Pin = LCD_BL_Pin;
  GPIO_InitStruct.Mode = GPIO_MODE_INPUT;
  GPIO_InitStruct.Pull = GPIO_NOPULL;
  HAL_GPIO_Init(LCD_BL_GPIO_Port, &GPIO_InitStruct);

  /*Configure GPIO pin : PK1 */
  GPIO_InitStruct.Pin = GPIO_PIN_1;
  GPIO_InitStruct.Mode = GPIO_MODE_OUTPUT_PP;
  GPIO_InitStruct.Pull = GPIO_NOPULL;
  GPIO_InitStruct.Speed = GPIO_SPEED_FREQ_LOW;
  HAL_GPIO_Init(GPIOK, &GPIO_InitStruct);

  /*Configure GPIO pins : MII_MDC_Pin MII_TXD2_Pin MII_TX_CLK_Pin MII_RXD0_Pin
                           MII_RXD1_Pin */
  GPIO_InitStruct.Pin = MII_MDC_Pin|MII_TXD2_Pin|MII_TX_CLK_Pin|MII_RXD0_Pin
                          |MII_RXD1_Pin;
  GPIO_InitStruct.Mode = GPIO_MODE_AF_PP;
  GPIO_InitStruct.Pull = GPIO_NOPULL;
  GPIO_InitStruct.Speed = GPIO_SPEED_FREQ_LOW;
  GPIO_InitStruct.Alternate = GPIO_AF11_ETH;
  HAL_GPIO_Init(GPIOC, &GPIO_InitStruct);

  /*Configure GPIO pins : MII_CRS_Pin MII_COL_Pin */
  GPIO_InitStruct.Pin = MII_CRS_Pin|MII_COL_Pin;
  GPIO_InitStruct.Mode = GPIO_MODE_AF_PP;
  GPIO_InitStruct.Pull = GPIO_NOPULL;
  GPIO_InitStruct.Speed = GPIO_SPEED_FREQ_LOW;
  GPIO_InitStruct.Alternate = GPIO_AF11_ETH;
  HAL_GPIO_Init(GPIOH, &GPIO_InitStruct);

  /*Configure GPIO pins : MII_MDIO_Pin MII_RX_CLK_Pin MII_RX_DV_Pin */
  GPIO_InitStruct.Pin = MII_MDIO_Pin|MII_RX_CLK_Pin|MII_RX_DV_Pin;
  GPIO_InitStruct.Mode = GPIO_MODE_AF_PP;
  GPIO_InitStruct.Pull = GPIO_NOPULL;
  GPIO_InitStruct.Speed = GPIO_SPEED_FREQ_LOW;
  GPIO_InitStruct.Alternate = GPIO_AF11_ETH;
  HAL_GPIO_Init(GPIOA, &GPIO_InitStruct);

  /*Configure GPIO pin : OTG_FS2_OverCurrent_Pin */
  GPIO_InitStruct.Pin = OTG_FS2_OverCurrent_Pin;
  GPIO_InitStruct.Mode = GPIO_MODE_IT_RISING;
  GPIO_InitStruct.Pull = GPIO_NOPULL;
  HAL_GPIO_Init(OTG_FS2_OverCurrent_GPIO_Port, &GPIO_InitStruct);

  /*Configure GPIO pin : PA6 */
  GPIO_InitStruct.Pin = GPIO_PIN_6;
  GPIO_InitStruct.Mode = GPIO_MODE_OUTPUT_PP;
  GPIO_InitStruct.Pull = GPIO_NOPULL;
  GPIO_InitStruct.Speed = GPIO_SPEED_FREQ_LOW;
  HAL_GPIO_Init(GPIOA, &GPIO_InitStruct);

  /*Configure GPIO pins : MII_TX_ER_nINT_Pin LCD_RST_Pin */
  GPIO_InitStruct.Pin = MII_TX_ER_nINT_Pin|LCD_RST_Pin;
  GPIO_InitStruct.Mode = GPIO_MODE_OUTPUT_PP;
  GPIO_InitStruct.Pull = GPIO_NOPULL;
  GPIO_InitStruct.Speed = GPIO_SPEED_FREQ_LOW;
  HAL_GPIO_Init(GPIOB, &GPIO_InitStruct);

  /*Configure GPIO pins : MII_RX_D3_Pin MII_RX_D2_Pin */
  GPIO_InitStruct.Pin = MII_RX_D3_Pin|MII_RX_D2_Pin;
  GPIO_InitStruct.Mode = GPIO_MODE_AF_PP;
  GPIO_InitStruct.Pull = GPIO_NOPULL;
  GPIO_InitStruct.Speed = GPIO_SPEED_FREQ_LOW;
  GPIO_InitStruct.Alternate = GPIO_AF11_ETH;
  HAL_GPIO_Init(GPIOB, &GPIO_InitStruct);

  /*Configure GPIO pin : LD1_Pin */
  GPIO_InitStruct.Pin = LD1_Pin;
  GPIO_InitStruct.Mode = GPIO_MODE_OUTPUT_PP;
  GPIO_InitStruct.Pull = GPIO_NOPULL;
  GPIO_InitStruct.Speed = GPIO_SPEED_FREQ_LOW;
  HAL_GPIO_Init(LD1_GPIO_Port, &GPIO_InitStruct);

}

void Error_Handler(void)
{
  __disable_irq();
  while (1)
  {
  }
}
